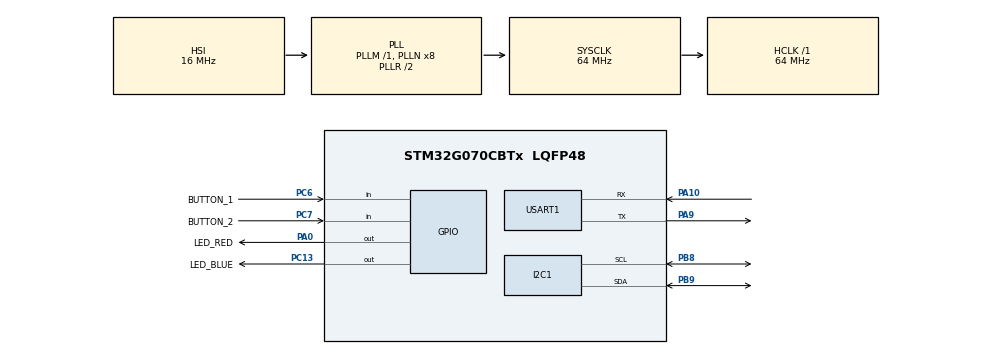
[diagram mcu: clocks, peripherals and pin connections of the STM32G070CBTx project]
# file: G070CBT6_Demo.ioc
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I2C1.Timing=0x10707DBC
Mcu.Family=STM32G0
Mcu.Name=STM32G070CBTx
Mcu.Package=LQFP48
PA0.GPIO_Label=LED_RED
PA0.Signal=GPIO_Output
PA10.Mode=Asynchronous
PA10.Signal=USART1_RX
PA9.Mode=Asynchronous
PA9.Signal=USART1_TX
PB8.Mode=I2C
PB8.Signal=I2C1_SCL
PB9.Mode=I2C
PB9.Signal=I2C1_SDA
PC13.GPIO_Label=LED_BLUE
PC13.GPIO_ModeDefaultOutputPP=GPIO_MODE_OUTPUT_PP
PC13.PinState=GPIO_PIN_SET
PC13.Signal=GPIO_Output
PC6.GPIO_Label=BUTTON_1
PC6.Signal=GPIO_Input
PC7.GPIO_Label=BUTTON_2
PC7.Signal=GPIO_Input
ProjectManager.HeapSize=0x200
ProjectManager.StackSize=0x400
ProjectManager.TargetToolchain=Makefile
RCC.ADCFreq_Value=64000000
RCC.AHBFreq_Value=64000000
RCC.CortexFreq_Value=64000000
RCC.EXTERNAL_CLOCK_VALUE=48000
RCC.HCLKFreq_Value=64000000
RCC.HSE_VALUE=8000000
RCC.HSI_VALUE=16000000
RCC.LSE_VALUE=32768
RCC.SYSCLKFreq_VALUE=64000000
RCC.SYSCLKSource=RCC_SYSCLKSOURCE_PLLCLK
RCC.VCOOutputFreq_Value=128000000
USART1.VirtualMode-Asynchronous=VM_ASYNC
VP_SYS_VS_DBSignals.Mode=DisableDeadBatterySignals
board=custom

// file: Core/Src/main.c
/* USER CODE BEGIN Header */
/**
  ******************************************************************************
  * @file           : main.c
  * @brief          : Main program body
  ******************************************************************************
  * @attention
  *
  * Copyright (c) 2022 STMicroelectronics.
  * All rights reserved.
  *
  * This software is licensed under terms that can be found in the LICENSE file
  * in the root directory of this software component.
  * If no LICENSE file comes with this software, it is provided AS-IS.
  *
  ******************************************************************************
  */
/* USER CODE END Header */
#include "main.h"

/* USER CODE BEGIN Includes */
#include "board.h"
/* USER CODE END Includes */

I2C_HandleTypeDef hi2c1;

UART_HandleTypeDef huart1;

void SystemClock_Config(void);
static void MX_GPIO_Init(void);
static void MX_I2C1_Init(void);
static void MX_USART1_UART_Init(void);

int main(void)
{

  /* MCU Configuration--------------------------------------------------------*/

  /* Reset of all peripherals, Initializes the Flash interface and the Systick. */
  HAL_Init();

  /* Configure the system clock */
  SystemClock_Config();

  /* Initialize all configured peripherals */
  MX_GPIO_Init();
  MX_I2C1_Init();
  MX_USART1_UART_Init();
  /* USER CODE BEGIN 2 */
  BOARD_Init();
  /* USER CODE END 2 */

  /* Infinite loop */
  while (1)
  {
    BOARD_Loop();
  }
}

void SystemClock_Config(void)
{
  RCC_OscInitTypeDef RCC_OscInitStruct = {0};
  RCC_ClkInitTypeDef RCC_ClkInitStruct = {0};

  /** Configure the main internal regulator output voltage
  */
  HAL_PWREx_ControlVoltageScaling(PWR_REGULATOR_VOLTAGE_SCALE1);

  /** Initializes the RCC Oscillators according to the specified parameters
  * in the RCC_OscInitTypeDef structure.
  */
  RCC_OscInitStruct.OscillatorType = RCC_OSCILLATORTYPE_HSI;
  RCC_OscInitStruct.HSIState = RCC_HSI_ON;
  RCC_OscInitStruct.HSIDiv = RCC_HSI_DIV1;
  RCC_OscInitStruct.HSICalibrationValue = RCC_HSICALIBRATION_DEFAULT;
  RCC_OscInitStruct.PLL.PLLState = RCC_PLL_ON;
  RCC_OscInitStruct.PLL.PLLSource = RCC_PLLSOURCE_HSI;
  RCC_OscInitStruct.PLL.PLLM = RCC_PLLM_DIV1;
  RCC_OscInitStruct.PLL.PLLN = 8;
  RCC_OscInitStruct.PLL.PLLP = RCC_PLLP_DIV2;
  RCC_OscInitStruct.PLL.PLLR = RCC_PLLR_DIV2;
  if (HAL_RCC_OscConfig(&RCC_OscInitStruct) != HAL_OK)
  {
    Error_Handler();
  }

  /** Initializes the CPU, AHB and APB buses clocks
  */
  RCC_ClkInitStruct.ClockType = RCC_CLOCKTYPE_HCLK|RCC_CLOCKTYPE_SYSCLK
                              |RCC_CLOCKTYPE_PCLK1;
  RCC_ClkInitStruct.SYSCLKSource = RCC_SYSCLKSOURCE_PLLCLK;
  RCC_ClkInitStruct.AHBCLKDivider = RCC_SYSCLK_DIV1;
  RCC_ClkInitStruct.APB1CLKDivider = RCC_HCLK_DIV1;

  if (HAL_RCC_ClockConfig(&RCC_ClkInitStruct, FLASH_LATENCY_2) != HAL_OK)
  {
    Error_Handler();
  }
}

static void MX_I2C1_Init(void)
{

  hi2c1.Instance = I2C1;
  hi2c1.Init.Timing = 0x10707DBC;
  hi2c1.Init.OwnAddress1 = 0;
  hi2c1.Init.AddressingMode = I2C_ADDRESSINGMODE_7BIT;
  hi2c1.Init.DualAddressMode = I2C_DUALADDRESS_DISABLE;
  hi2c1.Init.OwnAddress2 = 0;
  hi2c1.Init.OwnAddress2Masks = I2C_OA2_NOMASK;
  hi2c1.Init.GeneralCallMode = I2C_GENERALCALL_DISABLE;
  hi2c1.Init.NoStretchMode = I2C_NOSTRETCH_DISABLE;
  if (HAL_I2C_Init(&hi2c1) != HAL_OK)
  {
    Error_Handler();
  }

  /** Configure Analogue filter
  */
  if (HAL_I2CEx_ConfigAnalogFilter(&hi2c1, I2C_ANALOGFILTER_ENABLE) != HAL_OK)
  {
    Error_Handler();
  }

  /** Configure Digital filter
  */
  if (HAL_I2CEx_ConfigDigitalFilter(&hi2c1, 0) != HAL_OK)
  {
    Error_Handler();
  }

}

static void MX_USART1_UART_Init(void)
{

  huart1.Instance = USART1;
  huart1.Init.BaudRate = 115200;
  huart1.Init.WordLength = UART_WORDLENGTH_8B;
  huart1.Init.StopBits = UART_STOPBITS_1;
  huart1.Init.Parity = UART_PARITY_NONE;
  huart1.Init.Mode = UART_MODE_TX_RX;
  huart1.Init.HwFlowCtl = UART_HWCONTROL_NONE;
  huart1.Init.OverSampling = UART_OVERSAMPLING_16;
  huart1.Init.OneBitSampling = UART_ONE_BIT_SAMPLE_DISABLE;
  huart1.Init.ClockPrescaler = UART_PRESCALER_DIV1;
  huart1.AdvancedInit.AdvFeatureInit = UART_ADVFEATURE_NO_INIT;
  if (HAL_UART_Init(&huart1) != HAL_OK)
  {
    Error_Handler();
  }
  if (HAL_UARTEx_SetTxFifoThreshold(&huart1, UART_TXFIFO_THRESHOLD_1_8) != HAL_OK)
  {
    Error_Handler();
  }
  if (HAL_UARTEx_SetRxFifoThreshold(&huart1, UART_RXFIFO_THRESHOLD_1_8) != HAL_OK)
  {
    Error_Handler();
  }
  if (HAL_UARTEx_DisableFifoMode(&huart1) != HAL_OK)
  {
    Error_Handler();
  }

}

static void MX_GPIO_Init(void)
{
  GPIO_InitTypeDef GPIO_InitStruct = {0};

  /* GPIO Ports Clock Enable */
  __HAL_RCC_GPIOC_CLK_ENABLE();
  __HAL_RCC_GPIOA_CLK_ENABLE();
  __HAL_RCC_GPIOB_CLK_ENABLE();

  /*Configure GPIO pin Output Level */
  HAL_GPIO_WritePin(LED_BLUE_GPIO_Port, LED_BLUE_Pin, GPIO_PIN_SET);

  /*Configure GPIO pin Output Level */
  HAL_GPIO_WritePin(LED_RED_GPIO_Port, LED_RED_Pin, GPIO_PIN_RESET);

  /*Configure GPIO pin : LED_BLUE_Pin */
  GPIO_InitStruct.Pin = LED_BLUE_Pin;
  GPIO_InitStruct.Mode = GPIO_MODE_OUTPUT_PP;
  GPIO_InitStruct.Pull = GPIO_NOPULL;
  GPIO_InitStruct.Speed = GPIO_SPEED_FREQ_LOW;
  HAL_GPIO_Init(LED_BLUE_GPIO_Port, &GPIO_InitStruct);

  /*Configure GPIO pin : LED_RED_Pin */
  GPIO_InitStruct.Pin = LED_RED_Pin;
  GPIO_InitStruct.Mode = GPIO_MODE_OUTPUT_PP;
  GPIO_InitStruct.Pull = GPIO_NOPULL;
  GPIO_InitStruct.Speed = GPIO_SPEED_FREQ_LOW;
  HAL_GPIO_Init(LED_RED_GPIO_Port, &GPIO_InitStruct);

  /*Configure GPIO pins : BUTTON_1_Pin BUTTON_2_Pin */
  GPIO_InitStruct.Pin = BUTTON_1_Pin|BUTTON_2_Pin;
  GPIO_InitStruct.Mode = GPIO_MODE_INPUT;
  GPIO_InitStruct.Pull = GPIO_NOPULL;
  HAL_GPIO_Init(GPIOC, &GPIO_InitStruct);

}

void Error_Handler(void)
{
  /* USER CODE BEGIN Error_Handler_Debug */
#ifdef CONFIG_LED_ERROR
  /* Get Start Tick */
  int tickstart = HAL_GetTick();
  while (1)
  {
    HAL_GPIO_TogglePin(CONFIG_LED_ERROR_PORT, CONFIG_LED_ERROR_PIN);
    HAL_Delay(CONFIG_LED_ERROR_BLINK_MS);

    if((HAL_GetTick() - tickstart) > CONFIG_LED_ERROR_TIME_MS)
      break;
  }
#endif

  /* User can add his own implementation to report the HAL error return state */
  __disable_irq();
  /* reset chip */
  HAL_NVIC_SystemReset();
  /* USER CODE END Error_Handler_Debug */
}
